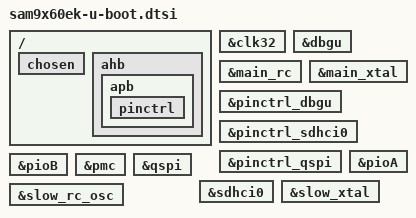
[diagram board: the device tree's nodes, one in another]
// SPDX-License-Identifier: (GPL-2.0+ OR MIT)
/*
 * sam9x60-u-boot.dts - Device Tree file for SAM9X60 SoC.
 *
 * Copyright (C) 2019 Microchip Technology Inc. and its subsidiaries
 */

/ {
	chosen {
		u-boot,dm-all;
	};

	ahb {
		u-boot,dm-all;

		apb {
			u-boot,dm-all;

			pinctrl {
				u-boot,dm-all;
			};
		};
	};
};

&clk32 {
	u-boot,dm-all;
};

&dbgu {
	u-boot,dm-all;
};

&main_rc {
	u-boot,dm-all;
};

&main_xtal {
	u-boot,dm-all;
};

&pinctrl_dbgu {
	u-boot,dm-all;
};

&pinctrl_sdhci0 {
	u-boot,dm-all;
};

&pinctrl_qspi {
	u-boot,dm-all;
};

&pioA {
	u-boot,dm-all;
};

&pioB {
	u-boot,dm-all;
};

&pmc {
	u-boot,dm-all;
};

&qspi {
	u-boot,dm-all;
};

&sdhci0 {
	u-boot,dm-all;
};

&slow_xtal {
	u-boot,dm-all;
};

&slow_rc_osc {
	u-boot,dm-all;
};
